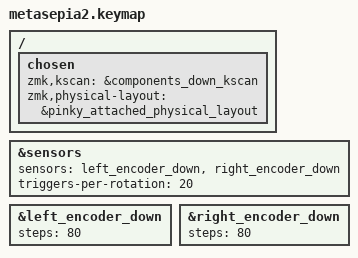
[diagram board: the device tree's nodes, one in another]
#include "include/metasepia2.dtsi"

&sensors {
     status = "okay";
     sensors = <&left_encoder_down &right_encoder_down>;
    triggers-per-rotation = <20>;
};

//&left_encoder_up { status = "okay"; steps = <80>; };
//&right_encoder_up { status = "okay"; steps = <80>; };
&left_encoder_down { status = "okay"; steps = <80>; };
&right_encoder_down { status = "okay"; steps = <80>; };

#include "include/base_keymap.dtsi"

/ {
    chosen {
        zmk,kscan = &components_down_kscan; // components_down_kscan or components_up_kscan
        zmk,physical-layout = &pinky_attached_physical_layout; // pinky_attached_physical_layout or pinky_detached_physical_layout
    };
};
